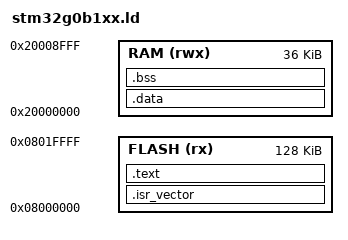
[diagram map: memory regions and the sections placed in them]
/* Minimal linker script for STM32G0B1 (addresses and sizes should be
 * checked against the exact MCU variant on the SKR-mini-E3-V3.0).
 */

MEMORY
{
    FLASH (rx)  : ORIGIN = 0x08000000, LENGTH = 128K
    RAM   (rwx) : ORIGIN = 0x20000000, LENGTH = 36K
}

ENTRY(Reset_Handler)

SECTIONS
{
    .isr_vector :
    {
        KEEP(*(.isr_vector))
    } > FLASH

    .text :
    {
        *(.text*)
        *(.rodata*)
        _etext = .;
    } > FLASH

    .data : AT (ADDR(.text) + SIZEOF(.text))
    {
        _sdata = .;
        *(.data*)
        _edata = .;
    } > RAM

    .bss :
    {
        _sbss = .;
        *(.bss*)
        *(COMMON)
        _ebss = .;
    } > RAM
}

